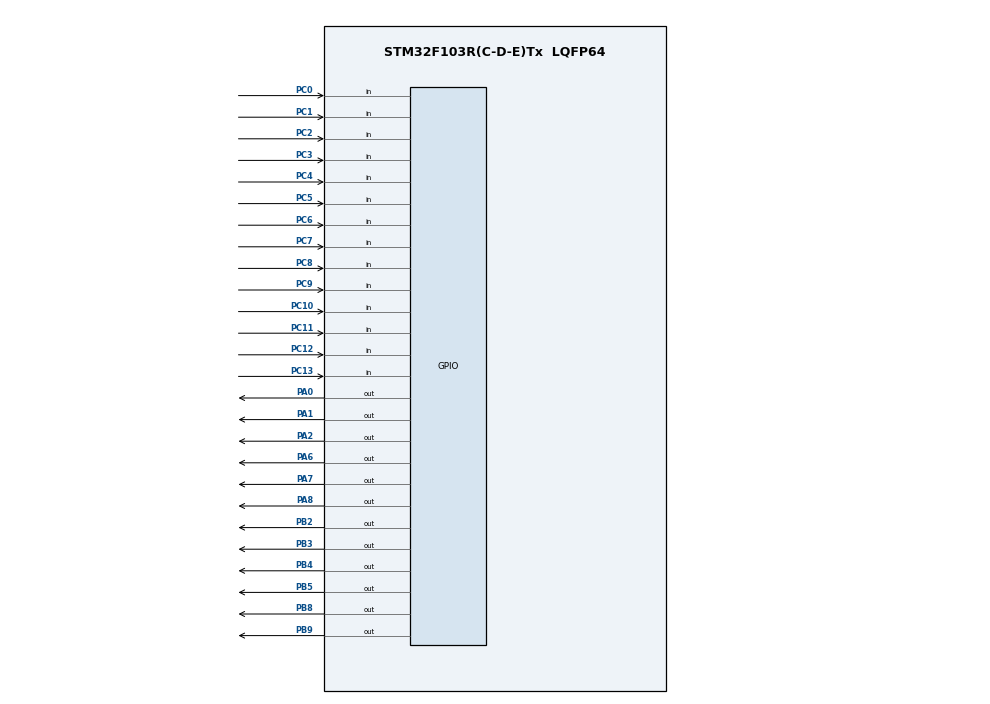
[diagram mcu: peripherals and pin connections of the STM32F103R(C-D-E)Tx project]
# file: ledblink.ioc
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Mcu.Family=STM32F1
Mcu.Name=STM32F103R(C-D-E)Tx
Mcu.Package=LQFP64
NVIC.PriorityGroup=NVIC_PRIORITYGROUP_4
PA0-WKUP.Signal=GPIO_Output
PA1.Signal=GPIO_Output
PA13.Mode=Serial_Wire
PA13.Signal=SYS_JTMS-SWDIO
PA14.Mode=Serial_Wire
PA14.Signal=SYS_JTCK-SWCLK
PA2.Signal=GPIO_Output
PA6.Signal=GPIO_Output
PA7.Signal=GPIO_Output
PA8.Signal=GPIO_Output
PB2.Signal=GPIO_Output
PB3.Signal=GPIO_Output
PB4.Signal=GPIO_Output
PB5.Signal=GPIO_Output
PB8.Signal=GPIO_Output
PB9.Signal=GPIO_Output
PC0.Signal=GPIO_Input
PC1.Signal=GPIO_Input
PC10.Signal=GPIO_Input
PC11.Signal=GPIO_Input
PC12.Signal=GPIO_Input
PC13-TAMPER-RTC.Signal=GPIO_Input
PC2.Signal=GPIO_Input
PC3.Signal=GPIO_Input
PC4.Signal=GPIO_Input
PC5.Signal=GPIO_Input
PC6.Signal=GPIO_Input
PC7.Signal=GPIO_Input
PC8.Signal=GPIO_Input
PC9.Signal=GPIO_Input
ProjectManager.HeapSize=0x200
ProjectManager.StackSize=0x400
ProjectManager.TargetToolchain=Makefile
RCC.APB1Freq_Value=8000000
RCC.APB2Freq_Value=8000000
board=custom

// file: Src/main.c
/* USER CODE BEGIN Header */
/**
  ******************************************************************************
  * @file           : main.c
  * @brief          : Main program body
  ******************************************************************************
  * @attention
  *
  * <h2><center>&copy; Copyright (c) 2019 STMicroelectronics.
  * All rights reserved.</center></h2>
  *
  * This software component is licensed by ST under BSD 3-Clause license,
  * the "License"; You may not use this file except in compliance with the
  * License. You may obtain a copy of the License at:
  *                        opensource.org/licenses/BSD-3-Clause
  *
  ******************************************************************************
  */
/* USER CODE END Header */

#include "main.h"

void SystemClock_Config(void);
static void MX_GPIO_Init(void);

int main(void)
{

  /* MCU Configuration--------------------------------------------------------*/

  /* Reset of all peripherals, Initializes the Flash interface and the Systick. */
  HAL_Init();

  /* Configure the system clock */
  SystemClock_Config();

  /* Initialize all configured peripherals */
  MX_GPIO_Init();

  /* Infinite loop */
  /* USER CODE BEGIN WHILE */
  uint32_t tick;
  tick = HAL_GetTick();
  while (1)
  {
    /* USER CODE END WHILE */
    if(HAL_GetTick() - tick >= 1000)
    {
      HAL_GPIO_TogglePin(GPIOD, GPIO_PIN_2);
      tick = HAL_GetTick();
    }
  }
}

void SystemClock_Config(void)
{
  RCC_OscInitTypeDef RCC_OscInitStruct = {0};
  RCC_ClkInitTypeDef RCC_ClkInitStruct = {0};

  /** Initializes the CPU, AHB and APB busses clocks
  */
  RCC_OscInitStruct.OscillatorType = RCC_OSCILLATORTYPE_HSI;
  RCC_OscInitStruct.HSIState = RCC_HSI_ON;
  RCC_OscInitStruct.HSICalibrationValue = RCC_HSICALIBRATION_DEFAULT;
  RCC_OscInitStruct.PLL.PLLState = RCC_PLL_NONE;
  if (HAL_RCC_OscConfig(&RCC_OscInitStruct) != HAL_OK)
  {
    Error_Handler();
  }
  /** Initializes the CPU, AHB and APB busses clocks
  */
  RCC_ClkInitStruct.ClockType = RCC_CLOCKTYPE_HCLK|RCC_CLOCKTYPE_SYSCLK
                              |RCC_CLOCKTYPE_PCLK1|RCC_CLOCKTYPE_PCLK2;
  RCC_ClkInitStruct.SYSCLKSource = RCC_SYSCLKSOURCE_HSI;
  RCC_ClkInitStruct.AHBCLKDivider = RCC_SYSCLK_DIV1;
  RCC_ClkInitStruct.APB1CLKDivider = RCC_HCLK_DIV1;
  RCC_ClkInitStruct.APB2CLKDivider = RCC_HCLK_DIV1;

  if (HAL_RCC_ClockConfig(&RCC_ClkInitStruct, FLASH_LATENCY_0) != HAL_OK)
  {
    Error_Handler();
  }
}

static void MX_GPIO_Init(void)
{
  GPIO_InitTypeDef GPIO_InitStruct = {0};

  /* GPIO Ports Clock Enable */
  __HAL_RCC_GPIOD_CLK_ENABLE();

  GPIO_InitStruct.Pin = GPIO_PIN_2;
  GPIO_InitStruct.Mode = GPIO_MODE_OUTPUT_PP;
  GPIO_InitStruct.Pull = GPIO_NOPULL;
  GPIO_InitStruct.Speed = GPIO_SPEED_FREQ_LOW;
  HAL_GPIO_Init(GPIOD, &GPIO_InitStruct);

  HAL_GPIO_WritePin(GPIOD, GPIO_PIN_2, GPIO_PIN_SET);

}

void Error_Handler(void)
{
}

/************************ (C) COPYRIGHT STMicroelectronics *****END OF FILE****/
